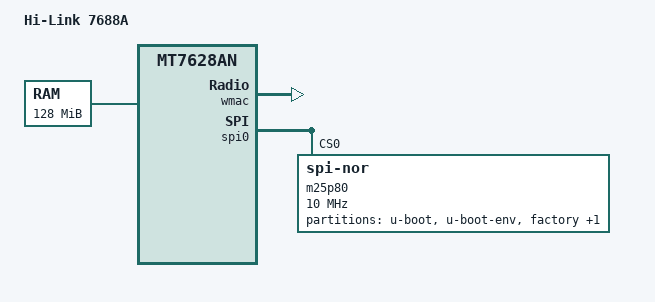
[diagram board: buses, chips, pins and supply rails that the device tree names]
/dts-v1/;

#include "mt7628an.dtsi"

/ {
	compatible = "mediatek,hi-link-7688a-board", "mediatek,mt7628an-soc";
	model = "Hi-Link 7688A";

	memory@0 {
		device_type = "memory";
		reg = <0x0 0x8000000>;
	};
};

&pinctrl {
	state_default: pinctrl0 {
		gpio {
			ralink,group = "i2c", "p0led_an", "p1led_an", "p2led_an", "p3led_an", "uart2", "pwm1";
			ralink,function = "gpio";
		};
	};
};

&wmac {
	status = "okay";
};

&spi0 {
	status = "okay";

	m25p80@0 {
		#address-cells = <1>;
		#size-cells = <1>;
		compatible = "jedec,spi-nor";
		reg = <0>;
		spi-max-frequency = <10000000>;
		m25p,chunked-io = <32>;

		partition@0 {
			label = "u-boot";
			reg = <0x0 0x30000>;
			read-only;
		};

		partition@30000 {
			label = "u-boot-env";
			reg = <0x30000 0x10000>;
			read-only;
		};

		factory: partition@40000 {
			label = "factory";
			reg = <0x40000 0x10000>;
			read-only;
		};

		partition@50000 {
			label = "firmware";
			reg = <0x50000 0x7b0000>;
		};
	};
};

&wmac {
	status = "okay";
};
